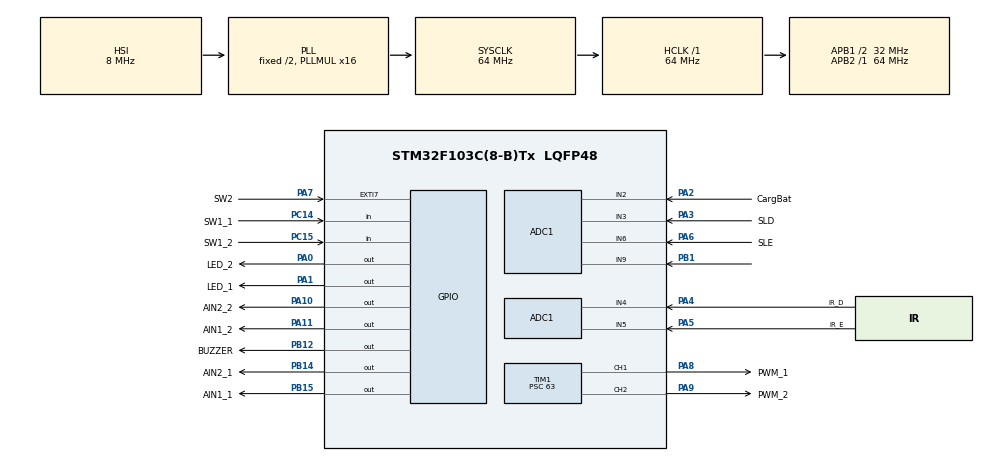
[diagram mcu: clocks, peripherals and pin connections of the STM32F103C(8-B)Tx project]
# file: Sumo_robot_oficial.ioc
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ADC1.Channel-0\#ChannelRegularConversion=ADC_CHANNEL_4
ADC1.Channel-1\#ChannelRegularConversion=ADC_CHANNEL_5
ADC1.Channel-2\#ChannelRegularConversion=ADC_CHANNEL_3
ADC1.Channel-3\#ChannelRegularConversion=ADC_CHANNEL_6
ADC1.Channel-4\#ChannelRegularConversion=ADC_CHANNEL_2
ADC1.Channel-5\#ChannelRegularConversion=ADC_CHANNEL_9
ADC1.ContinuousConvMode=ENABLE
ADC1.InjNumberOfConversion=0
ADC1.NbrOfConversion=6
ADC1.NbrOfConversionFlag=1
ADC1.Rank-0\#ChannelRegularConversion=1
ADC1.Rank-1\#ChannelRegularConversion=2
ADC1.Rank-2\#ChannelRegularConversion=3
ADC1.Rank-3\#ChannelRegularConversion=4
ADC1.Rank-4\#ChannelRegularConversion=5
ADC1.Rank-5\#ChannelRegularConversion=6
ADC1.SamplingTime-0\#ChannelRegularConversion=ADC_SAMPLETIME_28CYCLES_5
ADC1.SamplingTime-1\#ChannelRegularConversion=ADC_SAMPLETIME_28CYCLES_5
ADC1.SamplingTime-2\#ChannelRegularConversion=ADC_SAMPLETIME_28CYCLES_5
ADC1.SamplingTime-3\#ChannelRegularConversion=ADC_SAMPLETIME_28CYCLES_5
ADC1.SamplingTime-4\#ChannelRegularConversion=ADC_SAMPLETIME_28CYCLES_5
ADC1.SamplingTime-5\#ChannelRegularConversion=ADC_SAMPLETIME_28CYCLES_5
ADC1.master=1
Dma.ADC1.0.Direction=DMA_PERIPH_TO_MEMORY
Dma.ADC1.0.Instance=DMA1_Channel1
Dma.ADC1.0.MemDataAlignment=DMA_MDATAALIGN_HALFWORD
Dma.ADC1.0.MemInc=DMA_MINC_ENABLE
Dma.ADC1.0.Mode=DMA_CIRCULAR
Dma.ADC1.0.PeriphDataAlignment=DMA_PDATAALIGN_HALFWORD
Dma.ADC1.0.PeriphInc=DMA_PINC_DISABLE
Dma.ADC1.0.Priority=DMA_PRIORITY_LOW
Dma.Request0=ADC1
Mcu.Family=STM32F1
Mcu.Name=STM32F103C(8-B)Tx
Mcu.Package=LQFP48
NVIC.ADC1_2_IRQn=true\:1\:0\:true\:false\:true\:true\:true
NVIC.DMA1_Channel1_IRQn=true\:0\:0\:false\:false\:true\:false\:true
NVIC.EXTI9_5_IRQn=true\:2\:0\:true\:false\:true\:true\:true
NVIC.PriorityGroup=NVIC_PRIORITYGROUP_4
NVIC.TIM1_BRK_IRQn=true\:2\:0\:true\:false\:true\:true\:true
NVIC.TIM1_CC_IRQn=true\:2\:0\:true\:false\:true\:true\:true
NVIC.TIM1_TRG_COM_IRQn=true\:2\:0\:true\:false\:true\:true\:true
NVIC.TIM1_UP_IRQn=true\:2\:0\:true\:false\:true\:true\:true
PA0-WKUP.GPIO_Label=LED_2
PA0-WKUP.GPIO_PuPd=GPIO_NOPULL
PA0-WKUP.PinState=GPIO_PIN_RESET
PA0-WKUP.Signal=GPIO_Output
PA1.GPIO_Label=LED_1
PA1.GPIO_PuPd=GPIO_NOPULL
PA1.PinState=GPIO_PIN_RESET
PA1.Signal=GPIO_Output
PA10.GPIO_Label=AIN2_2
PA10.GPIO_PuPd=GPIO_NOPULL
PA10.PinState=GPIO_PIN_SET
PA10.Signal=GPIO_Output
PA11.GPIO_Label=AIN1_2
PA11.GPIO_PuPd=GPIO_NOPULL
PA11.PinState=GPIO_PIN_SET
PA11.Signal=GPIO_Output
PA13.Mode=Serial_Wire
PA13.Signal=SYS_JTMS-SWDIO
PA14.Mode=Serial_Wire
PA14.Signal=SYS_JTCK-SWCLK
PA2.GPIO_Label=CargBat
PA2.Signal=ADCx_IN2
PA3.GPIO_Label=SLD
PA3.Signal=ADCx_IN3
PA4.GPIO_Label=IR_D
PA4.Signal=ADCx_IN4
PA5.GPIO_Label=IR_E
PA5.Signal=ADCx_IN5
PA6.GPIO_Label=SLE
PA6.Signal=ADCx_IN6
PA7.GPIO_Label=SW2
PA7.GPIO_ModeDefaultEXTI=GPIO_MODE_IT_FALLING
PA7.GPIO_PuPd=GPIO_PULLUP
PA7.Signal=GPXTI7
PA8.GPIO_Label=PWM_1
PA8.Signal=S_TIM1_CH1
PA9.GPIO_Label=PWM_2
PA9.Signal=S_TIM1_CH2
PB1.Signal=ADCx_IN9
PB12.GPIO_Label=BUZZER
PB12.Signal=GPIO_Output
PB14.GPIO_Label=AIN2_1
PB14.GPIO_PuPd=GPIO_NOPULL
PB14.PinState=GPIO_PIN_SET
PB14.Signal=GPIO_Output
PB15.GPIO_Label=AIN1_1
PB15.GPIO_PuPd=GPIO_NOPULL
PB15.PinState=GPIO_PIN_SET
PB15.Signal=GPIO_Output
PC14-OSC32_IN.GPIO_Label=SW1_1
PC14-OSC32_IN.GPIO_PuPd=GPIO_PULLUP
PC14-OSC32_IN.Signal=GPIO_Input
PC15-OSC32_OUT.GPIO_Label=SW1_2
PC15-OSC32_OUT.GPIO_PuPd=GPIO_PULLUP
PC15-OSC32_OUT.Signal=GPIO_Input
ProjectManager.HeapSize=0x200
ProjectManager.StackSize=0x400
ProjectManager.TargetToolchain=STM32CubeIDE
RCC.ADCPresc=RCC_ADCPCLK2_DIV6
RCC.AHBFreq_Value=64000000
RCC.APB1CLKDivider=RCC_HCLK_DIV2
RCC.APB1Freq_Value=32000000
RCC.APB1TimFreq_Value=64000000
RCC.APB2Freq_Value=64000000
RCC.APB2TimFreq_Value=64000000
RCC.HCLKFreq_Value=64000000
RCC.PLLMUL=RCC_PLL_MUL16
RCC.SYSCLKFreq_VALUE=64000000
RCC.SYSCLKSource=RCC_SYSCLKSOURCE_PLLCLK
RCC.USBFreq_Value=64000000
SH.ADCx_IN2.0=ADC1_IN2,IN2
SH.ADCx_IN3.0=ADC1_IN3,IN3
SH.ADCx_IN4.0=ADC1_IN4,IN4
SH.ADCx_IN5.0=ADC1_IN5,IN5
SH.ADCx_IN6.0=ADC1_IN6,IN6
SH.ADCx_IN9.0=ADC1_IN9,IN9
SH.S_TIM1_CH1.0=TIM1_CH1,PWM Generation1 CH1
SH.S_TIM1_CH2.0=TIM1_CH2,PWM Generation2 CH2
TIM1.Channel-PWM\ Generation1\ CH1=TIM_CHANNEL_1
TIM1.Channel-PWM\ Generation2\ CH2=TIM_CHANNEL_2
TIM1.Period=19999
TIM1.Prescaler=63
TIM1.Pulse-PWM\ Generation1\ CH1=19999
TIM1.Pulse-PWM\ Generation2\ CH2=19999
VP_TIM1_VS_ClockSourceINT.Mode=Internal
board=custom

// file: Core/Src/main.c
/* USER CODE BEGIN Header */
/**
  ******************************************************************************
  * @file           : main.c
  * @brief          : Main program body
  ******************************************************************************
  * @attention
  *
  * <h2><center>&copy; Copyright (c) 2021 STMicroelectronics.
  * All rights reserved.</center></h2>
  *
  * This software component is licensed by ST under BSD 3-Clause license,
  * the "License"; You may not use this file except in compliance with the
  * License. You may obtain a copy of the License at:
  *                        opensource.org/licenses/BSD-3-Clause
  *
  ******************************************************************************
  */
/* USER CODE END Header */
#include "main.h"

/* USER CODE BEGIN Includes */
#include"app3.h"
#include"adc.h"
#include"motor3.h"
/* USER CODE END Includes */

ADC_HandleTypeDef hadc1;
DMA_HandleTypeDef hdma_adc1;

TIM_HandleTypeDef htim1;

void SystemClock_Config(void);
static void MX_GPIO_Init(void);
static void MX_DMA_Init(void);
static void MX_ADC1_Init(void);
static void MX_TIM1_Init(void);

int main(void)
{

  /* MCU Configuration--------------------------------------------------------*/

  /* Reset of all peripherals, Initializes the Flash interface and the Systick. */
  HAL_Init();

  /* Configure the system clock */
  SystemClock_Config();

  /* Initialize all configured peripherals */
  MX_GPIO_Init();
  MX_DMA_Init();
  MX_ADC1_Init();
  MX_TIM1_Init();
  /* USER CODE BEGIN 2 */
  app3_init();
  //adc_init();
  //motor3_init();
  /* USER CODE END 2 */

  /* Infinite loop */
  /* USER CODE BEGIN WHILE */
  while (1)
  {
	  app3_loop();
	  //setSpeeds(8000, 8000);
    /* USER CODE END WHILE */

  }
}

void SystemClock_Config(void)
{
  RCC_OscInitTypeDef RCC_OscInitStruct = {0};
  RCC_ClkInitTypeDef RCC_ClkInitStruct = {0};
  RCC_PeriphCLKInitTypeDef PeriphClkInit = {0};

  /** Initializes the RCC Oscillators according to the specified parameters
  * in the RCC_OscInitTypeDef structure.
  */
  RCC_OscInitStruct.OscillatorType = RCC_OSCILLATORTYPE_HSI;
  RCC_OscInitStruct.HSIState = RCC_HSI_ON;
  RCC_OscInitStruct.HSICalibrationValue = RCC_HSICALIBRATION_DEFAULT;
  RCC_OscInitStruct.PLL.PLLState = RCC_PLL_ON;
  RCC_OscInitStruct.PLL.PLLSource = RCC_PLLSOURCE_HSI_DIV2;
  RCC_OscInitStruct.PLL.PLLMUL = RCC_PLL_MUL16;
  if (HAL_RCC_OscConfig(&RCC_OscInitStruct) != HAL_OK)
  {
    Error_Handler();
  }
  /** Initializes the CPU, AHB and APB buses clocks
  */
  RCC_ClkInitStruct.ClockType = RCC_CLOCKTYPE_HCLK|RCC_CLOCKTYPE_SYSCLK
                              |RCC_CLOCKTYPE_PCLK1|RCC_CLOCKTYPE_PCLK2;
  RCC_ClkInitStruct.SYSCLKSource = RCC_SYSCLKSOURCE_PLLCLK;
  RCC_ClkInitStruct.AHBCLKDivider = RCC_SYSCLK_DIV1;
  RCC_ClkInitStruct.APB1CLKDivider = RCC_HCLK_DIV2;
  RCC_ClkInitStruct.APB2CLKDivider = RCC_HCLK_DIV1;

  if (HAL_RCC_ClockConfig(&RCC_ClkInitStruct, FLASH_LATENCY_2) != HAL_OK)
  {
    Error_Handler();
  }
  PeriphClkInit.PeriphClockSelection = RCC_PERIPHCLK_ADC;
  PeriphClkInit.AdcClockSelection = RCC_ADCPCLK2_DIV6;
  if (HAL_RCCEx_PeriphCLKConfig(&PeriphClkInit) != HAL_OK)
  {
    Error_Handler();
  }
}

static void MX_ADC1_Init(void)
{

  ADC_ChannelConfTypeDef sConfig = {0};

  /** Common config
  */
  hadc1.Instance = ADC1;
  hadc1.Init.ScanConvMode = ADC_SCAN_ENABLE;
  hadc1.Init.ContinuousConvMode = ENABLE;
  hadc1.Init.DiscontinuousConvMode = DISABLE;
  hadc1.Init.ExternalTrigConv = ADC_SOFTWARE_START;
  hadc1.Init.DataAlign = ADC_DATAALIGN_RIGHT;
  hadc1.Init.NbrOfConversion = 6;
  if (HAL_ADC_Init(&hadc1) != HAL_OK)
  {
    Error_Handler();
  }
  /** Configure Regular Channel
  */
  sConfig.Channel = ADC_CHANNEL_4;
  sConfig.Rank = ADC_REGULAR_RANK_1;
  sConfig.SamplingTime = ADC_SAMPLETIME_28CYCLES_5;
  if (HAL_ADC_ConfigChannel(&hadc1, &sConfig) != HAL_OK)
  {
    Error_Handler();
  }
  /** Configure Regular Channel
  */
  sConfig.Channel = ADC_CHANNEL_5;
  sConfig.Rank = ADC_REGULAR_RANK_2;
  if (HAL_ADC_ConfigChannel(&hadc1, &sConfig) != HAL_OK)
  {
    Error_Handler();
  }
  /** Configure Regular Channel
  */
  sConfig.Channel = ADC_CHANNEL_3;
  sConfig.Rank = ADC_REGULAR_RANK_3;
  if (HAL_ADC_ConfigChannel(&hadc1, &sConfig) != HAL_OK)
  {
    Error_Handler();
  }
  /** Configure Regular Channel
  */
  sConfig.Channel = ADC_CHANNEL_6;
  sConfig.Rank = ADC_REGULAR_RANK_4;
  if (HAL_ADC_ConfigChannel(&hadc1, &sConfig) != HAL_OK)
  {
    Error_Handler();
  }
  /** Configure Regular Channel
  */
  sConfig.Channel = ADC_CHANNEL_2;
  sConfig.Rank = ADC_REGULAR_RANK_5;
  if (HAL_ADC_ConfigChannel(&hadc1, &sConfig) != HAL_OK)
  {
    Error_Handler();
  }
  /** Configure Regular Channel
  */
  sConfig.Channel = ADC_CHANNEL_9;
  sConfig.Rank = ADC_REGULAR_RANK_6;
  if (HAL_ADC_ConfigChannel(&hadc1, &sConfig) != HAL_OK)
  {
    Error_Handler();
  }

}

static void MX_TIM1_Init(void)
{

  TIM_ClockConfigTypeDef sClockSourceConfig = {0};
  TIM_MasterConfigTypeDef sMasterConfig = {0};
  TIM_OC_InitTypeDef sConfigOC = {0};
  TIM_BreakDeadTimeConfigTypeDef sBreakDeadTimeConfig = {0};

  htim1.Instance = TIM1;
  htim1.Init.Prescaler = 63;
  htim1.Init.CounterMode = TIM_COUNTERMODE_UP;
  htim1.Init.Period = 19999;
  htim1.Init.ClockDivision = TIM_CLOCKDIVISION_DIV1;
  htim1.Init.RepetitionCounter = 0;
  htim1.Init.AutoReloadPreload = TIM_AUTORELOAD_PRELOAD_DISABLE;
  if (HAL_TIM_Base_Init(&htim1) != HAL_OK)
  {
    Error_Handler();
  }
  sClockSourceConfig.ClockSource = TIM_CLOCKSOURCE_INTERNAL;
  if (HAL_TIM_ConfigClockSource(&htim1, &sClockSourceConfig) != HAL_OK)
  {
    Error_Handler();
  }
  if (HAL_TIM_PWM_Init(&htim1) != HAL_OK)
  {
    Error_Handler();
  }
  sMasterConfig.MasterOutputTrigger = TIM_TRGO_RESET;
  sMasterConfig.MasterSlaveMode = TIM_MASTERSLAVEMODE_DISABLE;
  if (HAL_TIMEx_MasterConfigSynchronization(&htim1, &sMasterConfig) != HAL_OK)
  {
    Error_Handler();
  }
  sConfigOC.OCMode = TIM_OCMODE_PWM1;
  sConfigOC.Pulse = 19999;
  sConfigOC.OCPolarity = TIM_OCPOLARITY_HIGH;
  sConfigOC.OCNPolarity = TIM_OCNPOLARITY_HIGH;
  sConfigOC.OCFastMode = TIM_OCFAST_DISABLE;
  sConfigOC.OCIdleState = TIM_OCIDLESTATE_RESET;
  sConfigOC.OCNIdleState = TIM_OCNIDLESTATE_RESET;
  if (HAL_TIM_PWM_ConfigChannel(&htim1, &sConfigOC, TIM_CHANNEL_1) != HAL_OK)
  {
    Error_Handler();
  }
  if (HAL_TIM_PWM_ConfigChannel(&htim1, &sConfigOC, TIM_CHANNEL_2) != HAL_OK)
  {
    Error_Handler();
  }
  sBreakDeadTimeConfig.OffStateRunMode = TIM_OSSR_DISABLE;
  sBreakDeadTimeConfig.OffStateIDLEMode = TIM_OSSI_DISABLE;
  sBreakDeadTimeConfig.LockLevel = TIM_LOCKLEVEL_OFF;
  sBreakDeadTimeConfig.DeadTime = 0;
  sBreakDeadTimeConfig.BreakState = TIM_BREAK_DISABLE;
  sBreakDeadTimeConfig.BreakPolarity = TIM_BREAKPOLARITY_HIGH;
  sBreakDeadTimeConfig.AutomaticOutput = TIM_AUTOMATICOUTPUT_DISABLE;
  if (HAL_TIMEx_ConfigBreakDeadTime(&htim1, &sBreakDeadTimeConfig) != HAL_OK)
  {
    Error_Handler();
  }
  HAL_TIM_MspPostInit(&htim1);

}

static void MX_DMA_Init(void)
{

  /* DMA controller clock enable */
  __HAL_RCC_DMA1_CLK_ENABLE();

  /* DMA interrupt init */
  /* DMA1_Channel1_IRQn interrupt configuration */
  HAL_NVIC_SetPriority(DMA1_Channel1_IRQn, 0, 0);
  HAL_NVIC_EnableIRQ(DMA1_Channel1_IRQn);

}

static void MX_GPIO_Init(void)
{
  GPIO_InitTypeDef GPIO_InitStruct = {0};

  /* GPIO Ports Clock Enable */
  __HAL_RCC_GPIOC_CLK_ENABLE();
  __HAL_RCC_GPIOA_CLK_ENABLE();
  __HAL_RCC_GPIOB_CLK_ENABLE();

  /*Configure GPIO pin Output Level */
  HAL_GPIO_WritePin(GPIOA, LED_2_Pin|LED_1_Pin, GPIO_PIN_RESET);

  /*Configure GPIO pin Output Level */
  HAL_GPIO_WritePin(BUZZER_GPIO_Port, BUZZER_Pin, GPIO_PIN_RESET);

  /*Configure GPIO pin Output Level */
  HAL_GPIO_WritePin(GPIOB, AIN2_1_Pin|AIN1_1_Pin, GPIO_PIN_SET);

  /*Configure GPIO pin Output Level */
  HAL_GPIO_WritePin(GPIOA, AIN2_2_Pin|AIN1_2_Pin, GPIO_PIN_SET);

  /*Configure GPIO pins : SW1_1_Pin SW1_2_Pin */
  GPIO_InitStruct.Pin = SW1_1_Pin|SW1_2_Pin;
  GPIO_InitStruct.Mode = GPIO_MODE_INPUT;
  GPIO_InitStruct.Pull = GPIO_PULLUP;
  HAL_GPIO_Init(GPIOC, &GPIO_InitStruct);

  /*Configure GPIO pins : LED_2_Pin LED_1_Pin AIN2_2_Pin AIN1_2_Pin */
  GPIO_InitStruct.Pin = LED_2_Pin|LED_1_Pin|AIN2_2_Pin|AIN1_2_Pin;
  GPIO_InitStruct.Mode = GPIO_MODE_OUTPUT_PP;
  GPIO_InitStruct.Pull = GPIO_NOPULL;
  GPIO_InitStruct.Speed = GPIO_SPEED_FREQ_LOW;
  HAL_GPIO_Init(GPIOA, &GPIO_InitStruct);

  /*Configure GPIO pin : SW2_Pin */
  GPIO_InitStruct.Pin = SW2_Pin;
  GPIO_InitStruct.Mode = GPIO_MODE_IT_FALLING;
  GPIO_InitStruct.Pull = GPIO_PULLUP;
  HAL_GPIO_Init(SW2_GPIO_Port, &GPIO_InitStruct);

  /*Configure GPIO pins : BUZZER_Pin AIN2_1_Pin AIN1_1_Pin */
  GPIO_InitStruct.Pin = BUZZER_Pin|AIN2_1_Pin|AIN1_1_Pin;
  GPIO_InitStruct.Mode = GPIO_MODE_OUTPUT_PP;
  GPIO_InitStruct.Pull = GPIO_NOPULL;
  GPIO_InitStruct.Speed = GPIO_SPEED_FREQ_LOW;
  HAL_GPIO_Init(GPIOB, &GPIO_InitStruct);

  /* EXTI interrupt init*/
  HAL_NVIC_SetPriority(EXTI9_5_IRQn, 2, 0);
  HAL_NVIC_EnableIRQ(EXTI9_5_IRQn);

}

void Error_Handler(void)
{
  __disable_irq();
  while (1)
  {
  }
}

/************************ (C) COPYRIGHT STMicroelectronics *****END OF FILE****/
